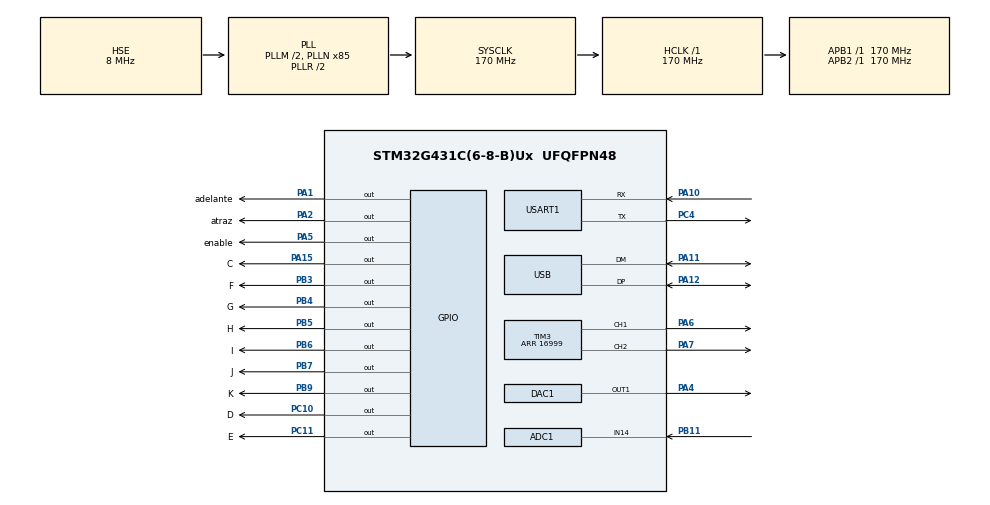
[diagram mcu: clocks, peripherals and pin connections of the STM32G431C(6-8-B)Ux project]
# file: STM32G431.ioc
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ADC1.Channel-5\#ChannelRegularConversion=ADC_CHANNEL_14
ADC1.ContinuousConvMode=ENABLE
ADC1.DMAContinuousRequests=ENABLE
ADC1.NbrOfConversionFlag=1
ADC1.OffsetNumber-5\#ChannelRegularConversion=ADC_OFFSET_NONE
ADC1.Rank-5\#ChannelRegularConversion=1
ADC1.SamplingTime-5\#ChannelRegularConversion=ADC_SAMPLETIME_24CYCLES_5
ADC1.master=1
DAC1.DAC_DMADoubleDataMode-DAC_OUT1=DISABLE
DAC1.DAC_HighFrequency_OUT1-DAC_OUT1=DAC_HIGH_FREQUENCY_INTERFACE_MODE_ABOVE_80MHZ
DAC1.DAC_Trigger_OUT1-DAC_OUT1=DAC_TRIGGER_T15_TRGO
Dma.ADC1.5.Direction=DMA_PERIPH_TO_MEMORY
Dma.ADC1.5.EventEnable=DISABLE
Dma.ADC1.5.Instance=DMA1_Channel3
Dma.ADC1.5.MemDataAlignment=DMA_MDATAALIGN_WORD
Dma.ADC1.5.MemInc=DMA_MINC_ENABLE
Dma.ADC1.5.Mode=DMA_CIRCULAR
Dma.ADC1.5.PeriphDataAlignment=DMA_PDATAALIGN_WORD
Dma.ADC1.5.PeriphInc=DMA_PINC_DISABLE
Dma.ADC1.5.Polarity=HAL_DMAMUX_REQ_GEN_RISING
Dma.ADC1.5.Priority=DMA_PRIORITY_LOW
Dma.ADC1.5.RequestNumber=1
Dma.ADC1.5.SignalID=NONE
Dma.ADC1.5.SyncEnable=DISABLE
Dma.ADC1.5.SyncPolarity=HAL_DMAMUX_SYNC_NO_EVENT
Dma.ADC1.5.SyncRequestNumber=1
Dma.ADC1.5.SyncSignalID=NONE
Dma.DAC1_CH1.2.Direction=DMA_MEMORY_TO_PERIPH
Dma.DAC1_CH1.2.EventEnable=DISABLE
Dma.DAC1_CH1.2.Instance=DMA1_Channel4
Dma.DAC1_CH1.2.MemDataAlignment=DMA_MDATAALIGN_WORD
Dma.DAC1_CH1.2.MemInc=DMA_MINC_ENABLE
Dma.DAC1_CH1.2.Mode=DMA_CIRCULAR
Dma.DAC1_CH1.2.PeriphDataAlignment=DMA_PDATAALIGN_WORD
Dma.DAC1_CH1.2.PeriphInc=DMA_PINC_DISABLE
Dma.DAC1_CH1.2.Polarity=HAL_DMAMUX_REQ_GEN_RISING
Dma.DAC1_CH1.2.Priority=DMA_PRIORITY_HIGH
Dma.DAC1_CH1.2.RequestNumber=1
Dma.DAC1_CH1.2.SignalID=NONE
Dma.DAC1_CH1.2.SyncEnable=DISABLE
Dma.DAC1_CH1.2.SyncPolarity=HAL_DMAMUX_SYNC_NO_EVENT
Dma.DAC1_CH1.2.SyncRequestNumber=1
Dma.DAC1_CH1.2.SyncSignalID=NONE
Dma.Request0=USART1_RX
Dma.Request1=USART1_TX
Dma.Request2=DAC1_CH1
Dma.Request3=TIM3_CH1
Dma.Request4=TIM3_CH2
Dma.Request5=ADC1
Dma.TIM3_CH1.3.Direction=DMA_MEMORY_TO_PERIPH
Dma.TIM3_CH1.3.EventEnable=DISABLE
Dma.TIM3_CH1.3.Instance=DMA1_Channel5
Dma.TIM3_CH1.3.MemDataAlignment=DMA_MDATAALIGN_HALFWORD
Dma.TIM3_CH1.3.MemInc=DMA_MINC_ENABLE
Dma.TIM3_CH1.3.Mode=DMA_CIRCULAR
Dma.TIM3_CH1.3.PeriphDataAlignment=DMA_PDATAALIGN_HALFWORD
Dma.TIM3_CH1.3.PeriphInc=DMA_PINC_DISABLE
Dma.TIM3_CH1.3.Polarity=HAL_DMAMUX_REQ_GEN_RISING
Dma.TIM3_CH1.3.Priority=DMA_PRIORITY_LOW
Dma.TIM3_CH1.3.RequestNumber=1
Dma.TIM3_CH1.3.SignalID=NONE
Dma.TIM3_CH1.3.SyncEnable=DISABLE
Dma.TIM3_CH1.3.SyncPolarity=HAL_DMAMUX_SYNC_NO_EVENT
Dma.TIM3_CH1.3.SyncRequestNumber=1
Dma.TIM3_CH1.3.SyncSignalID=NONE
Dma.TIM3_CH2.4.Direction=DMA_MEMORY_TO_PERIPH
Dma.TIM3_CH2.4.EventEnable=DISABLE
Dma.TIM3_CH2.4.Instance=DMA1_Channel6
Dma.TIM3_CH2.4.MemDataAlignment=DMA_MDATAALIGN_HALFWORD
Dma.TIM3_CH2.4.MemInc=DMA_MINC_ENABLE
Dma.TIM3_CH2.4.Mode=DMA_CIRCULAR
Dma.TIM3_CH2.4.PeriphDataAlignment=DMA_PDATAALIGN_HALFWORD
Dma.TIM3_CH2.4.PeriphInc=DMA_PINC_DISABLE
Dma.TIM3_CH2.4.Polarity=HAL_DMAMUX_REQ_GEN_RISING
Dma.TIM3_CH2.4.Priority=DMA_PRIORITY_LOW
Dma.TIM3_CH2.4.RequestNumber=1
Dma.TIM3_CH2.4.SignalID=NONE
Dma.TIM3_CH2.4.SyncEnable=DISABLE
Dma.TIM3_CH2.4.SyncPolarity=HAL_DMAMUX_SYNC_NO_EVENT
Dma.TIM3_CH2.4.SyncRequestNumber=1
Dma.TIM3_CH2.4.SyncSignalID=NONE
Dma.USART1_RX.0.Direction=DMA_PERIPH_TO_MEMORY
Dma.USART1_RX.0.EventEnable=DISABLE
Dma.USART1_RX.0.Instance=DMA1_Channel1
Dma.USART1_RX.0.MemDataAlignment=DMA_MDATAALIGN_BYTE
Dma.USART1_RX.0.MemInc=DMA_MINC_ENABLE
Dma.USART1_RX.0.Mode=DMA_NORMAL
Dma.USART1_RX.0.PeriphDataAlignment=DMA_PDATAALIGN_BYTE
Dma.USART1_RX.0.PeriphInc=DMA_PINC_DISABLE
Dma.USART1_RX.0.Polarity=HAL_DMAMUX_REQ_GEN_RISING
Dma.USART1_RX.0.Priority=DMA_PRIORITY_LOW
Dma.USART1_RX.0.RequestNumber=1
Dma.USART1_RX.0.SignalID=NONE
Dma.USART1_RX.0.SyncEnable=DISABLE
Dma.USART1_RX.0.SyncPolarity=HAL_DMAMUX_SYNC_NO_EVENT
Dma.USART1_RX.0.SyncRequestNumber=1
Dma.USART1_RX.0.SyncSignalID=NONE
Dma.USART1_TX.1.Direction=DMA_MEMORY_TO_PERIPH
Dma.USART1_TX.1.EventEnable=DISABLE
Dma.USART1_TX.1.Instance=DMA1_Channel2
Dma.USART1_TX.1.MemDataAlignment=DMA_MDATAALIGN_BYTE
Dma.USART1_TX.1.MemInc=DMA_MINC_ENABLE
Dma.USART1_TX.1.Mode=DMA_NORMAL
Dma.USART1_TX.1.PeriphDataAlignment=DMA_PDATAALIGN_BYTE
Dma.USART1_TX.1.PeriphInc=DMA_PINC_DISABLE
Dma.USART1_TX.1.Polarity=HAL_DMAMUX_REQ_GEN_RISING
Dma.USART1_TX.1.Priority=DMA_PRIORITY_LOW
Dma.USART1_TX.1.RequestNumber=1
Dma.USART1_TX.1.SignalID=NONE
Dma.USART1_TX.1.SyncEnable=DISABLE
Dma.USART1_TX.1.SyncPolarity=HAL_DMAMUX_SYNC_NO_EVENT
Dma.USART1_TX.1.SyncRequestNumber=1
Dma.USART1_TX.1.SyncSignalID=NONE
Mcu.Family=STM32G4
Mcu.Name=STM32G431C(6-8-B)Ux
Mcu.Package=UFQFPN48
NVIC.DMA1_Channel1_IRQn=true\:0\:0\:false\:false\:true\:false\:true\:true
NVIC.DMA1_Channel2_IRQn=true\:0\:0\:false\:false\:true\:false\:true\:true
NVIC.PriorityGroup=NVIC_PRIORITYGROUP_4
NVIC.TIM1_BRK_TIM15_IRQn=true\:0\:0\:false\:false\:true\:true\:true\:true
NVIC.TIM2_IRQn=true\:0\:0\:false\:false\:true\:true\:true\:true
NVIC.TIM7_IRQn=true\:0\:0\:false\:false\:true\:true\:true\:true
NVIC.USART1_IRQn=true\:0\:0\:false\:false\:true\:true\:true\:true
NVIC.USB_LP_IRQn=true\:0\:0\:false\:false\:true\:false\:true\:true
PA1.GPIO_Label=adelante
PA1.GPIO_Speed=GPIO_SPEED_FREQ_MEDIUM
PA1.PinState=GPIO_PIN_SET
PA1.Signal=GPIO_Output
PA10.Mode=Asynchronous
PA10.Signal=USART1_RX
PA11.Mode=Device
PA11.Signal=USB_DM
PA12.Mode=Device
PA12.Signal=USB_DP
PA15.GPIO_Label=C
PA15.GPIO_Speed=GPIO_SPEED_FREQ_MEDIUM
PA15.Signal=GPIO_Output
PA2.GPIO_Label=atraz
PA2.GPIO_Speed=GPIO_SPEED_FREQ_MEDIUM
PA2.Signal=GPIO_Output
PA4.Signal=COMP_DAC11_group
PA5.GPIO_Label=enable
PA5.GPIO_Speed=GPIO_SPEED_FREQ_MEDIUM
PA5.PinState=GPIO_PIN_SET
PA5.Signal=GPIO_Output
PA6.Signal=S_TIM3_CH1
PA7.Signal=S_TIM3_CH2
PB11.Mode=IN14-Single-Ended
PB11.Signal=ADC1_IN14
PB3.GPIO_Label=F
PB3.GPIO_Speed=GPIO_SPEED_FREQ_HIGH
PB3.Signal=GPIO_Output
PB4.GPIO_Label=G
PB4.GPIO_Speed=GPIO_SPEED_FREQ_MEDIUM
PB4.Signal=GPIO_Output
PB5.GPIO_Label=H
PB5.GPIO_Speed=GPIO_SPEED_FREQ_MEDIUM
PB5.Signal=GPIO_Output
PB6.GPIO_Label=I
PB6.GPIO_Speed=GPIO_SPEED_FREQ_MEDIUM
PB6.Signal=GPIO_Output
PB7.GPIO_Label=J
PB7.GPIO_Speed=GPIO_SPEED_FREQ_MEDIUM
PB7.Signal=GPIO_Output
PB9.GPIO_Label=K
PB9.GPIO_Speed=GPIO_SPEED_FREQ_MEDIUM
PB9.Signal=GPIO_Output
PC10.GPIO_Label=D
PC10.GPIO_PuPd=GPIO_NOPULL
PC10.GPIO_Speed=GPIO_SPEED_FREQ_MEDIUM
PC10.Signal=GPIO_Output
PC11.GPIO_Label=E
PC11.GPIO_Speed=GPIO_SPEED_FREQ_MEDIUM
PC11.Signal=GPIO_Output
PC4.Mode=Asynchronous
PC4.Signal=USART1_TX
PF0-OSC_IN.Mode=HSE-External-Oscillator
PF0-OSC_IN.Signal=RCC_OSC_IN
PF1-OSC_OUT.Mode=HSE-External-Oscillator
PF1-OSC_OUT.Signal=RCC_OSC_OUT
ProjectManager.HeapSize=0x200
ProjectManager.StackSize=0x400
ProjectManager.TargetToolchain=STM32CubeIDE
RCC.ADC12Freq_Value=170000000
RCC.AHBFreq_Value=170000000
RCC.APB1Freq_Value=170000000
RCC.APB1TimFreq_Value=170000000
RCC.APB2Freq_Value=170000000
RCC.APB2TimFreq_Value=170000000
RCC.CK48CLockSelection=RCC_USBCLKSOURCE_HSI48
RCC.CortexFreq_Value=170000000
RCC.EXTERNAL_CLOCK_VALUE=12288000
RCC.HCLKFreq_Value=170000000
RCC.HSE_VALUE=8000000
RCC.HSI48_VALUE=48000000
RCC.HSI_VALUE=16000000
RCC.LSE_VALUE=32768
RCC.PLLM=RCC_PLLM_DIV2
RCC.PLLN=85
RCC.PLLSourceVirtual=RCC_PLLSOURCE_HSE
RCC.SYSCLKFreq_VALUE=170000000
RCC.SYSCLKSource=RCC_SYSCLKSOURCE_PLLCLK
RCC.USBFreq_Value=48000000
RCC.VCOOutputFreq_Value=340000000
SH.COMP_DAC11_group.0=DAC1_OUT1,DAC_OUT1
SH.S_TIM3_CH1.0=TIM3_CH1,PWM Generation1 CH1
SH.S_TIM3_CH2.0=TIM3_CH2,PWM Generation2 CH2
TIM15.AutoReloadPreload=TIM_AUTORELOAD_PRELOAD_ENABLE
TIM15.PeriodNoDither=42499
TIM15.Prescaler=1
TIM15.TIM_MasterOutputTrigger=TIM_TRGO_UPDATE
TIM2.AutoReloadPreload=TIM_AUTORELOAD_PRELOAD_ENABLE
TIM2.PeriodNoDither=85000000
TIM3.AutoReloadPreload=TIM_AUTORELOAD_PRELOAD_ENABLE
TIM3.Channel-PWM\ Generation1\ CH1=TIM_CHANNEL_1
TIM3.Channel-PWM\ Generation2\ CH2=TIM_CHANNEL_2
TIM3.PeriodNoDither=16999
TIM7.AutoReloadPreload=TIM_AUTORELOAD_PRELOAD_ENABLE
TIM7.PeriodNoDither=8500
TIM7.Prescaler=4
USART1.VirtualMode-Asynchronous=VM_ASYNC
USB_DEVICE.CLASS_NAME_FS=CDC
USB_DEVICE.USBD_DEBUG_LEVEL=3
USB_DEVICE.VirtualMode=Cdc
USB_DEVICE.VirtualModeFS=Cdc_FS
VP_SYS_VS_DBSignals.Mode=DisableDeadBatterySignals
VP_TIM15_VS_ClockSourceINT.Mode=Internal
VP_TIM2_VS_ClockSourceINT.Mode=Internal
VP_TIM3_VS_ClockSourceINT.Mode=Internal
VP_TIM7_VS_ClockSourceINT.Mode=Enable_Timer
VP_USB_DEVICE_VS_USB_DEVICE_CDC_FS.Mode=CDC_FS
board=custom

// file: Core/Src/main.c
/* USER CODE BEGIN Header */
/**
  ******************************************************************************
  * @file           : main.c
  * @brief          : Main program body
  ******************************************************************************
  * @attention
  *
  * Copyright (c) 2024 STMicroelectronics.
  * All rights reserved.
  *
  * This software is licensed under terms that can be found in the LICENSE file
  * in the root directory of this software component.
  * If no LICENSE file comes with this software, it is provided AS-IS.
  *
  ******************************************************************************
  */
/* USER CODE END Header */
#include "main.h"
#include "usb_device.h"

/* USER CODE BEGIN Includes */
#include "principal.h"
/* USER CODE END Includes */

ADC_HandleTypeDef hadc1;
DMA_HandleTypeDef hdma_adc1;

DAC_HandleTypeDef hdac1;
DMA_HandleTypeDef hdma_dac1_ch1;

TIM_HandleTypeDef htim2;
TIM_HandleTypeDef htim3;
TIM_HandleTypeDef htim7;
TIM_HandleTypeDef htim15;
DMA_HandleTypeDef hdma_tim3_ch1;
DMA_HandleTypeDef hdma_tim3_ch2;

UART_HandleTypeDef huart1;
DMA_HandleTypeDef hdma_usart1_rx;
DMA_HandleTypeDef hdma_usart1_tx;

void SystemClock_Config(void);
static void MX_GPIO_Init(void);
static void MX_DMA_Init(void);
static void MX_USART1_UART_Init(void);
static void MX_ADC1_Init(void);
static void MX_TIM15_Init(void);
static void MX_DAC1_Init(void);
static void MX_TIM3_Init(void);
static void MX_TIM7_Init(void);
static void MX_TIM2_Init(void);

int main(void)
{

  /* MCU Configuration--------------------------------------------------------*/

  /* Reset of all peripherals, Initializes the Flash interface and the Systick. */
  HAL_Init();

  /* Configure the system clock */
  SystemClock_Config();

  /* Initialize all configured peripherals */
  MX_GPIO_Init();
  MX_DMA_Init();
  MX_USART1_UART_Init();
  MX_USB_Device_Init();
  MX_ADC1_Init();
  MX_TIM15_Init();
  MX_DAC1_Init();
  MX_TIM3_Init();
  MX_TIM7_Init();
  MX_TIM2_Init();
  /* USER CODE BEGIN 2 */

   setup();
  /* USER CODE END 2 */

  /* Infinite loop */
  while (1)
  {

  }
}

void SystemClock_Config(void)
{
  RCC_OscInitTypeDef RCC_OscInitStruct = {0};
  RCC_ClkInitTypeDef RCC_ClkInitStruct = {0};

  /** Configure the main internal regulator output voltage
  */
  HAL_PWREx_ControlVoltageScaling(PWR_REGULATOR_VOLTAGE_SCALE1_BOOST);

  /** Initializes the RCC Oscillators according to the specified parameters
  * in the RCC_OscInitTypeDef structure.
  */
  RCC_OscInitStruct.OscillatorType = RCC_OSCILLATORTYPE_HSI48|RCC_OSCILLATORTYPE_HSE;
  RCC_OscInitStruct.HSEState = RCC_HSE_ON;
  RCC_OscInitStruct.HSI48State = RCC_HSI48_ON;
  RCC_OscInitStruct.PLL.PLLState = RCC_PLL_ON;
  RCC_OscInitStruct.PLL.PLLSource = RCC_PLLSOURCE_HSE;
  RCC_OscInitStruct.PLL.PLLM = RCC_PLLM_DIV2;
  RCC_OscInitStruct.PLL.PLLN = 85;
  RCC_OscInitStruct.PLL.PLLP = RCC_PLLP_DIV2;
  RCC_OscInitStruct.PLL.PLLQ = RCC_PLLQ_DIV2;
  RCC_OscInitStruct.PLL.PLLR = RCC_PLLR_DIV2;
  if (HAL_RCC_OscConfig(&RCC_OscInitStruct) != HAL_OK)
  {
    Error_Handler();
  }

  /** Initializes the CPU, AHB and APB buses clocks
  */
  RCC_ClkInitStruct.ClockType = RCC_CLOCKTYPE_HCLK|RCC_CLOCKTYPE_SYSCLK
                              |RCC_CLOCKTYPE_PCLK1|RCC_CLOCKTYPE_PCLK2;
  RCC_ClkInitStruct.SYSCLKSource = RCC_SYSCLKSOURCE_PLLCLK;
  RCC_ClkInitStruct.AHBCLKDivider = RCC_SYSCLK_DIV1;
  RCC_ClkInitStruct.APB1CLKDivider = RCC_HCLK_DIV1;
  RCC_ClkInitStruct.APB2CLKDivider = RCC_HCLK_DIV1;

  if (HAL_RCC_ClockConfig(&RCC_ClkInitStruct, FLASH_LATENCY_4) != HAL_OK)
  {
    Error_Handler();
  }
}

static void MX_ADC1_Init(void)
{

  ADC_MultiModeTypeDef multimode = {0};
  ADC_ChannelConfTypeDef sConfig = {0};

  /** Common config
  */
  hadc1.Instance = ADC1;
  hadc1.Init.ClockPrescaler = ADC_CLOCK_SYNC_PCLK_DIV4;
  hadc1.Init.Resolution = ADC_RESOLUTION_12B;
  hadc1.Init.DataAlign = ADC_DATAALIGN_RIGHT;
  hadc1.Init.GainCompensation = 0;
  hadc1.Init.ScanConvMode = ADC_SCAN_DISABLE;
  hadc1.Init.EOCSelection = ADC_EOC_SINGLE_CONV;
  hadc1.Init.LowPowerAutoWait = DISABLE;
  hadc1.Init.ContinuousConvMode = ENABLE;
  hadc1.Init.NbrOfConversion = 1;
  hadc1.Init.DiscontinuousConvMode = DISABLE;
  hadc1.Init.ExternalTrigConv = ADC_SOFTWARE_START;
  hadc1.Init.ExternalTrigConvEdge = ADC_EXTERNALTRIGCONVEDGE_NONE;
  hadc1.Init.DMAContinuousRequests = ENABLE;
  hadc1.Init.Overrun = ADC_OVR_DATA_PRESERVED;
  hadc1.Init.OversamplingMode = DISABLE;
  if (HAL_ADC_Init(&hadc1) != HAL_OK)
  {
    Error_Handler();
  }

  /** Configure the ADC multi-mode
  */
  multimode.Mode = ADC_MODE_INDEPENDENT;
  if (HAL_ADCEx_MultiModeConfigChannel(&hadc1, &multimode) != HAL_OK)
  {
    Error_Handler();
  }

  /** Configure Regular Channel
  */
  sConfig.Channel = ADC_CHANNEL_14;
  sConfig.Rank = ADC_REGULAR_RANK_1;
  sConfig.SamplingTime = ADC_SAMPLETIME_24CYCLES_5;
  sConfig.SingleDiff = ADC_SINGLE_ENDED;
  sConfig.OffsetNumber = ADC_OFFSET_NONE;
  sConfig.Offset = 0;
  if (HAL_ADC_ConfigChannel(&hadc1, &sConfig) != HAL_OK)
  {
    Error_Handler();
  }

}

static void MX_DAC1_Init(void)
{

  DAC_ChannelConfTypeDef sConfig = {0};

  /** DAC Initialization
  */
  hdac1.Instance = DAC1;
  if (HAL_DAC_Init(&hdac1) != HAL_OK)
  {
    Error_Handler();
  }

  /** DAC channel OUT1 config
  */
  sConfig.DAC_HighFrequency = DAC_HIGH_FREQUENCY_INTERFACE_MODE_ABOVE_80MHZ;
  sConfig.DAC_DMADoubleDataMode = DISABLE;
  sConfig.DAC_SignedFormat = DISABLE;
  sConfig.DAC_SampleAndHold = DAC_SAMPLEANDHOLD_DISABLE;
  sConfig.DAC_Trigger = DAC_TRIGGER_T15_TRGO;
  sConfig.DAC_Trigger2 = DAC_TRIGGER_NONE;
  sConfig.DAC_OutputBuffer = DAC_OUTPUTBUFFER_ENABLE;
  sConfig.DAC_ConnectOnChipPeripheral = DAC_CHIPCONNECT_EXTERNAL;
  sConfig.DAC_UserTrimming = DAC_TRIMMING_FACTORY;
  if (HAL_DAC_ConfigChannel(&hdac1, &sConfig, DAC_CHANNEL_1) != HAL_OK)
  {
    Error_Handler();
  }

}

static void MX_TIM2_Init(void)
{

  TIM_ClockConfigTypeDef sClockSourceConfig = {0};
  TIM_MasterConfigTypeDef sMasterConfig = {0};

  htim2.Instance = TIM2;
  htim2.Init.Prescaler = 0;
  htim2.Init.CounterMode = TIM_COUNTERMODE_UP;
  htim2.Init.Period = 85000000;
  htim2.Init.ClockDivision = TIM_CLOCKDIVISION_DIV1;
  htim2.Init.AutoReloadPreload = TIM_AUTORELOAD_PRELOAD_ENABLE;
  if (HAL_TIM_Base_Init(&htim2) != HAL_OK)
  {
    Error_Handler();
  }
  sClockSourceConfig.ClockSource = TIM_CLOCKSOURCE_INTERNAL;
  if (HAL_TIM_ConfigClockSource(&htim2, &sClockSourceConfig) != HAL_OK)
  {
    Error_Handler();
  }
  sMasterConfig.MasterOutputTrigger = TIM_TRGO_RESET;
  sMasterConfig.MasterSlaveMode = TIM_MASTERSLAVEMODE_DISABLE;
  if (HAL_TIMEx_MasterConfigSynchronization(&htim2, &sMasterConfig) != HAL_OK)
  {
    Error_Handler();
  }

}

static void MX_TIM3_Init(void)
{

  TIM_ClockConfigTypeDef sClockSourceConfig = {0};
  TIM_MasterConfigTypeDef sMasterConfig = {0};
  TIM_OC_InitTypeDef sConfigOC = {0};

  htim3.Instance = TIM3;
  htim3.Init.Prescaler = 0;
  htim3.Init.CounterMode = TIM_COUNTERMODE_UP;
  htim3.Init.Period = 16999;
  htim3.Init.ClockDivision = TIM_CLOCKDIVISION_DIV1;
  htim3.Init.AutoReloadPreload = TIM_AUTORELOAD_PRELOAD_ENABLE;
  if (HAL_TIM_Base_Init(&htim3) != HAL_OK)
  {
    Error_Handler();
  }
  sClockSourceConfig.ClockSource = TIM_CLOCKSOURCE_INTERNAL;
  if (HAL_TIM_ConfigClockSource(&htim3, &sClockSourceConfig) != HAL_OK)
  {
    Error_Handler();
  }
  if (HAL_TIM_PWM_Init(&htim3) != HAL_OK)
  {
    Error_Handler();
  }
  sMasterConfig.MasterOutputTrigger = TIM_TRGO_RESET;
  sMasterConfig.MasterSlaveMode = TIM_MASTERSLAVEMODE_DISABLE;
  if (HAL_TIMEx_MasterConfigSynchronization(&htim3, &sMasterConfig) != HAL_OK)
  {
    Error_Handler();
  }
  sConfigOC.OCMode = TIM_OCMODE_PWM1;
  sConfigOC.Pulse = 0;
  sConfigOC.OCPolarity = TIM_OCPOLARITY_HIGH;
  sConfigOC.OCFastMode = TIM_OCFAST_DISABLE;
  if (HAL_TIM_PWM_ConfigChannel(&htim3, &sConfigOC, TIM_CHANNEL_1) != HAL_OK)
  {
    Error_Handler();
  }
  if (HAL_TIM_PWM_ConfigChannel(&htim3, &sConfigOC, TIM_CHANNEL_2) != HAL_OK)
  {
    Error_Handler();
  }
  HAL_TIM_MspPostInit(&htim3);

}

static void MX_TIM7_Init(void)
{

  TIM_MasterConfigTypeDef sMasterConfig = {0};

  htim7.Instance = TIM7;
  htim7.Init.Prescaler = 4;
  htim7.Init.CounterMode = TIM_COUNTERMODE_UP;
  htim7.Init.Period = 8500;
  htim7.Init.AutoReloadPreload = TIM_AUTORELOAD_PRELOAD_ENABLE;
  if (HAL_TIM_Base_Init(&htim7) != HAL_OK)
  {
    Error_Handler();
  }
  sMasterConfig.MasterOutputTrigger = TIM_TRGO_RESET;
  sMasterConfig.MasterSlaveMode = TIM_MASTERSLAVEMODE_DISABLE;
  if (HAL_TIMEx_MasterConfigSynchronization(&htim7, &sMasterConfig) != HAL_OK)
  {
    Error_Handler();
  }

}

static void MX_TIM15_Init(void)
{

  TIM_ClockConfigTypeDef sClockSourceConfig = {0};
  TIM_MasterConfigTypeDef sMasterConfig = {0};

  htim15.Instance = TIM15;
  htim15.Init.Prescaler = 1;
  htim15.Init.CounterMode = TIM_COUNTERMODE_UP;
  htim15.Init.Period = 42499;
  htim15.Init.ClockDivision = TIM_CLOCKDIVISION_DIV1;
  htim15.Init.RepetitionCounter = 0;
  htim15.Init.AutoReloadPreload = TIM_AUTORELOAD_PRELOAD_ENABLE;
  if (HAL_TIM_Base_Init(&htim15) != HAL_OK)
  {
    Error_Handler();
  }
  sClockSourceConfig.ClockSource = TIM_CLOCKSOURCE_INTERNAL;
  if (HAL_TIM_ConfigClockSource(&htim15, &sClockSourceConfig) != HAL_OK)
  {
    Error_Handler();
  }
  sMasterConfig.MasterOutputTrigger = TIM_TRGO_UPDATE;
  sMasterConfig.MasterSlaveMode = TIM_MASTERSLAVEMODE_DISABLE;
  if (HAL_TIMEx_MasterConfigSynchronization(&htim15, &sMasterConfig) != HAL_OK)
  {
    Error_Handler();
  }

}

static void MX_USART1_UART_Init(void)
{

  huart1.Instance = USART1;
  huart1.Init.BaudRate = 115200;
  huart1.Init.WordLength = UART_WORDLENGTH_8B;
  huart1.Init.StopBits = UART_STOPBITS_1;
  huart1.Init.Parity = UART_PARITY_NONE;
  huart1.Init.Mode = UART_MODE_TX_RX;
  huart1.Init.HwFlowCtl = UART_HWCONTROL_NONE;
  huart1.Init.OverSampling = UART_OVERSAMPLING_16;
  huart1.Init.OneBitSampling = UART_ONE_BIT_SAMPLE_DISABLE;
  huart1.Init.ClockPrescaler = UART_PRESCALER_DIV1;
  huart1.AdvancedInit.AdvFeatureInit = UART_ADVFEATURE_NO_INIT;
  if (HAL_UART_Init(&huart1) != HAL_OK)
  {
    Error_Handler();
  }
  if (HAL_UARTEx_SetTxFifoThreshold(&huart1, UART_TXFIFO_THRESHOLD_1_8) != HAL_OK)
  {
    Error_Handler();
  }
  if (HAL_UARTEx_SetRxFifoThreshold(&huart1, UART_RXFIFO_THRESHOLD_1_8) != HAL_OK)
  {
    Error_Handler();
  }
  if (HAL_UARTEx_DisableFifoMode(&huart1) != HAL_OK)
  {
    Error_Handler();
  }

}

static void MX_DMA_Init(void)
{

  /* DMA controller clock enable */
  __HAL_RCC_DMAMUX1_CLK_ENABLE();
  __HAL_RCC_DMA1_CLK_ENABLE();

  /* DMA interrupt init */
  /* DMA1_Channel1_IRQn interrupt configuration */
  HAL_NVIC_SetPriority(DMA1_Channel1_IRQn, 0, 0);
  HAL_NVIC_EnableIRQ(DMA1_Channel1_IRQn);
  /* DMA1_Channel2_IRQn interrupt configuration */
  HAL_NVIC_SetPriority(DMA1_Channel2_IRQn, 0, 0);
  HAL_NVIC_EnableIRQ(DMA1_Channel2_IRQn);

}

static void MX_GPIO_Init(void)
{
  GPIO_InitTypeDef GPIO_InitStruct = {0};

  /* GPIO Ports Clock Enable */
  __HAL_RCC_GPIOF_CLK_ENABLE();
  __HAL_RCC_GPIOA_CLK_ENABLE();
  __HAL_RCC_GPIOC_CLK_ENABLE();
  __HAL_RCC_GPIOB_CLK_ENABLE();

  /*Configure GPIO pin Output Level */
  HAL_GPIO_WritePin(GPIOA, adelante_Pin|enable_Pin, GPIO_PIN_SET);

  /*Configure GPIO pin Output Level */
  HAL_GPIO_WritePin(GPIOA, atraz_Pin|C_Pin, GPIO_PIN_RESET);

  /*Configure GPIO pin Output Level */
  HAL_GPIO_WritePin(GPIOC, D_Pin|E_Pin, GPIO_PIN_RESET);

  /*Configure GPIO pin Output Level */
  HAL_GPIO_WritePin(GPIOB, F_Pin|G_Pin|H_Pin|I_Pin
                          |J_Pin|K_Pin, GPIO_PIN_RESET);

  /*Configure GPIO pins : adelante_Pin atraz_Pin enable_Pin C_Pin */
  GPIO_InitStruct.Pin = adelante_Pin|atraz_Pin|enable_Pin|C_Pin;
  GPIO_InitStruct.Mode = GPIO_MODE_OUTPUT_PP;
  GPIO_InitStruct.Pull = GPIO_NOPULL;
  GPIO_InitStruct.Speed = GPIO_SPEED_FREQ_MEDIUM;
  HAL_GPIO_Init(GPIOA, &GPIO_InitStruct);

  /*Configure GPIO pins : D_Pin E_Pin */
  GPIO_InitStruct.Pin = D_Pin|E_Pin;
  GPIO_InitStruct.Mode = GPIO_MODE_OUTPUT_PP;
  GPIO_InitStruct.Pull = GPIO_NOPULL;
  GPIO_InitStruct.Speed = GPIO_SPEED_FREQ_MEDIUM;
  HAL_GPIO_Init(GPIOC, &GPIO_InitStruct);

  /*Configure GPIO pin : F_Pin */
  GPIO_InitStruct.Pin = F_Pin;
  GPIO_InitStruct.Mode = GPIO_MODE_OUTPUT_PP;
  GPIO_InitStruct.Pull = GPIO_NOPULL;
  GPIO_InitStruct.Speed = GPIO_SPEED_FREQ_HIGH;
  HAL_GPIO_Init(F_GPIO_Port, &GPIO_InitStruct);

  /*Configure GPIO pins : G_Pin H_Pin I_Pin J_Pin
                           K_Pin */
  GPIO_InitStruct.Pin = G_Pin|H_Pin|I_Pin|J_Pin
                          |K_Pin;
  GPIO_InitStruct.Mode = GPIO_MODE_OUTPUT_PP;
  GPIO_InitStruct.Pull = GPIO_NOPULL;
  GPIO_InitStruct.Speed = GPIO_SPEED_FREQ_MEDIUM;
  HAL_GPIO_Init(GPIOB, &GPIO_InitStruct);

}

void Error_Handler(void)
{
  __disable_irq();
  while (1)
  {
  }
}
